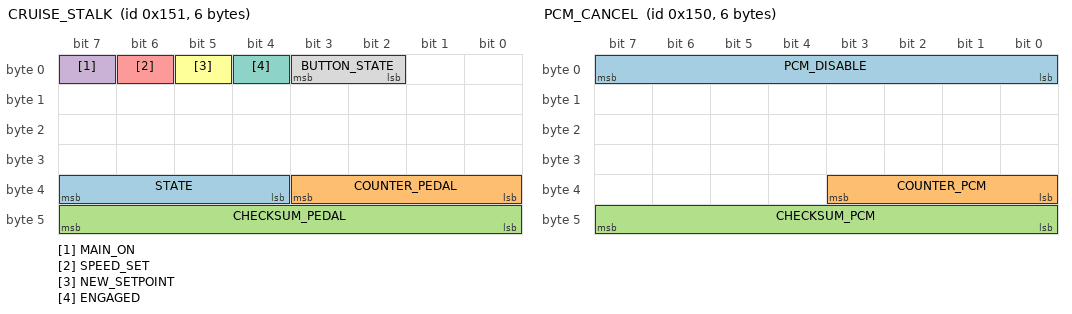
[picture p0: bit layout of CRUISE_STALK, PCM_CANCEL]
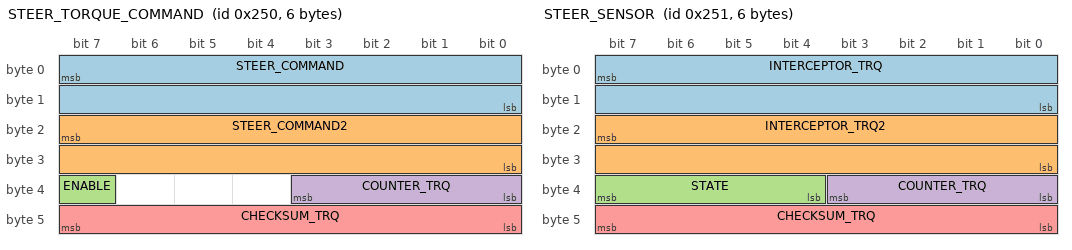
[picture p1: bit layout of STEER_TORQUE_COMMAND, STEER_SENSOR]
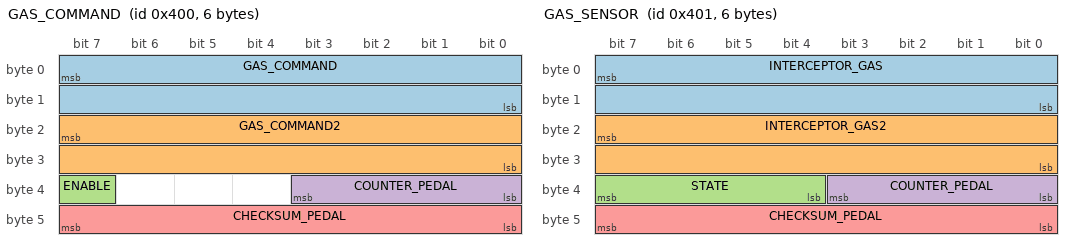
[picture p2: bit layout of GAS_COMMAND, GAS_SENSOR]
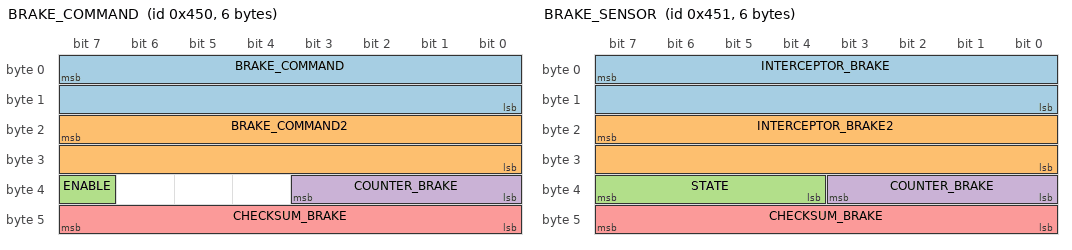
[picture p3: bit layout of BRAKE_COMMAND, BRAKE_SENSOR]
 BO_ 337 CRUISE_STALK: 6 INTERCEPTOR
  SG_ STATE : 39|4@0+ (1,0) [0|15] "" EON
  SG_ COUNTER_PEDAL : 35|4@0+ (1,0) [0|15] "" EON
  SG_ CHECKSUM_PEDAL : 47|8@0+ (1,0) [0|255] "" EON
  SG_ MAIN_ON : 7|1@0+ (1,0) [0|1] "" EON
  SG_ SPEED_SET : 6|1@0+ (1,0) [0|16383] "" XXX
  SG_ NEW_SETPOINT : 5|1@0+ (1,0) [0|3] "" XXX
  SG_ ENGAGED : 4|1@0+ (1,0) [0|3] "" XXX
  SG_ BUTTON_STATE : 2|2@1+ (1,0) [0|3] "" XXX

 BO_ 336 PCM_CANCEL: 6 EON
  SG_ PCM_DISABLE : 7|8@0+ (1,0) [0|1] "" INTERCEPTOR
  SG_ COUNTER_PCM : 35|4@0+ (1,0) [0|15] "" INTERCEPTOR
  SG_ CHECKSUM_PCM : 47|8@0+ (1,0) [0|255] "" INTERCEPTOR

 BO_ 592 STEER_TORQUE_COMMAND: 6 EON
  SG_ STEER_COMMAND : 7|16@0+ (1,0) [0|1] "" INTERCEPTOR
  SG_ STEER_COMMAND2 : 23|16@0+ (-1,0) [0|1] "" INTERCEPTOR
  SG_ ENABLE : 39|1@0+ (1,0) [0|1] "" INTERCEPTOR
  SG_ COUNTER_TRQ : 35|4@0+ (1,0) [0|15] "" INTERCEPTOR
  SG_ CHECKSUM_TRQ : 47|8@0+ (1,0) [0|255] "" INTERCEPTOR

 BO_ 593 STEER_SENSOR: 6 INTERCEPTOR
  SG_ INTERCEPTOR_TRQ : 7|16@0+ (0.00169433593750,-2.5) [0|1] "" EON
  SG_ INTERCEPTOR_TRQ2 : 23|16@0+ (0.00169433593750,-2.5) [0|1] "" EON
  SG_ STATE : 39|4@0+ (1,0) [0|15] "" EON
  SG_ COUNTER_TRQ : 35|4@0+ (1,0) [0|15] "" EON
  SG_ CHECKSUM_TRQ : 47|8@0+ (1,0) [0|255] "" EON

 VAL_ 593 STATE 5 "FAULT_TIMEOUT" 4 "FAULT_STARTUP" 3 "FAULT_SCE" 2 "FAULT_SEND" 1 "FAULT_BAD_CHECKSUM" 0 "NO_FAULT" ;

 BO_ 1024 GAS_COMMAND: 6 EON
  SG_ GAS_COMMAND : 7|16@0+ (0.882353,-2888.8235) [0|1] "" INTERCEPTOR
  SG_ GAS_COMMAND2 : 23|16@0+ (0.882353,-2888.8235) [0|1] "" INTERCEPTOR
  SG_ ENABLE : 39|1@0+ (1,0) [0|1] "" INTERCEPTOR
  SG_ COUNTER_PEDAL : 35|4@0+ (1,0) [0|15] "" INTERCEPTOR
  SG_ CHECKSUM_PEDAL : 47|8@0+ (1,0) [0|255] "" INTERCEPTOR

 BO_ 1025 GAS_SENSOR: 6 INTERCEPTOR
  SG_ INTERCEPTOR_GAS : 7|16@0+ (1,0) [0|1] "" EON
  SG_ INTERCEPTOR_GAS2 : 23|16@0+ (1,0) [0|1] "" EON
  SG_ STATE : 39|4@0+ (1,0) [0|15] "" EON
  SG_ COUNTER_PEDAL : 35|4@0+ (1,0) [0|15] "" EON
  SG_ CHECKSUM_PEDAL : 47|8@0+ (1,0) [0|255] "" EON

 VAL_ 1025 STATE 5 "FAULT_TIMEOUT" 4 "FAULT_STARTUP" 3 "FAULT_SCE" 2 "FAULT_SEND" 1 "FAULT_BAD_CHECKSUM" 0 "NO_FAULT" ;

 BO_ 1104 BRAKE_COMMAND: 6 EON
  SG_ BRAKE_COMMAND : 7|16@0+ (0.882353,-2888.8235) [0|1] "" INTERCEPTOR
  SG_ BRAKE_COMMAND2 : 23|16@0+ (1,0) [0|1] "" INTERCEPTOR
  SG_ ENABLE : 39|1@0+ (1,0) [0|1] "" INTERCEPTOR
  SG_ COUNTER_BRAKE : 35|4@0+ (1,0) [0|15] "" INTERCEPTOR
  SG_ CHECKSUM_BRAKE : 47|8@0+ (1,0) [0|255] "" INTERCEPTOR

 BO_ 1105 BRAKE_SENSOR: 6 INTERCEPTOR
  SG_ INTERCEPTOR_BRAKE : 7|16@0+ (1,0) [0|1] "" EON
  SG_ INTERCEPTOR_BRAKE2 : 23|16@0+ (1,0) [0|1] "" EON
  SG_ STATE : 39|4@0+ (1,0) [0|15] "" EON
  SG_ COUNTER_BRAKE : 35|4@0+ (1,0) [0|15] "" EON
  SG_ CHECKSUM_BRAKE : 47|8@0+ (1,0) [0|255] "" EON

 VAL_ 1105 STATE 5 "FAULT_TIMEOUT" 4 "FAULT_STARTUP" 3 "FAULT_SCE" 2 "FAULT_SEND" 1 "FAULT_BAD_CHECKSUM" 0 "NO_FAULT" ;

VERSION ""

NS_ :

BS_:

BU_: XXX

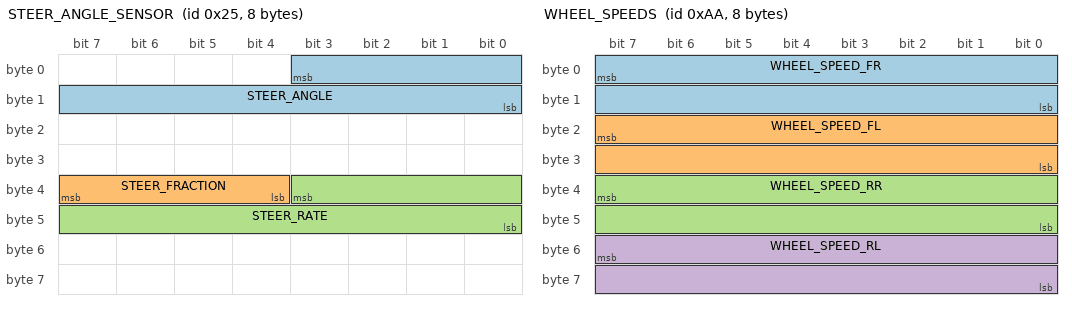
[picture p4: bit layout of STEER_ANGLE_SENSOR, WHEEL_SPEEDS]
BO_ 37 STEER_ANGLE_SENSOR: 8 XXX
 SG_ STEER_ANGLE : 3|12@0- (1.5,132) [-500|500] "deg" XXX
 SG_ STEER_FRACTION : 39|4@0- (0.1,0) [-0.7|0.7] "deg" XXX
 SG_ STEER_RATE : 35|12@0- (1,0) [-2000|2000] "deg/s" XXX

BO_ 170 WHEEL_SPEEDS: 8 XXX
 SG_ WHEEL_SPEED_FR : 7|16@0+ (0.01,-67.67) [0|250] "kph" XXX
 SG_ WHEEL_SPEED_FL : 23|16@0+ (0.01,-67.67) [0|250] "kph" XXX
 SG_ WHEEL_SPEED_RR : 39|16@0+ (0.01,-67.67) [0|250] "kph" XXX
 SG_ WHEEL_SPEED_RL : 55|16@0+ (0.01,-67.67) [0|250] "kph" XXX

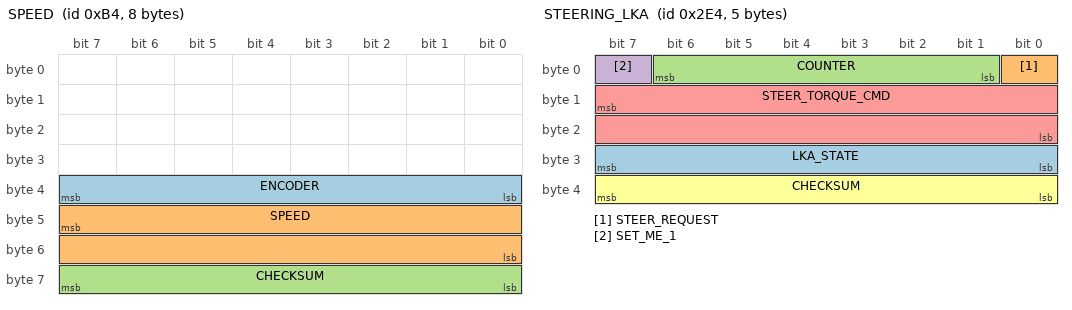
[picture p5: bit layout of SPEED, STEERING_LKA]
BO_ 180 SPEED: 8 XXX
 SG_ ENCODER : 39|8@0+ (1,0) [0|255] "" XXX
 SG_ SPEED : 47|16@0+ (0.01,0) [0|250] "kph" XXX
 SG_ CHECKSUM : 63|8@0+ (1,0) [0|255] "" XXX

BO_ 740 STEERING_LKA: 5 XXX
 SG_ LKA_STATE : 31|8@0+ (1,0) [0|255] "" XXX
 SG_ STEER_REQUEST : 0|1@0+ (1,0) [0|1] "" XXX
 SG_ COUNTER : 6|6@0+ (1,0) [0|63] "" XXX
 SG_ SET_ME_1 : 7|1@0+ (1,0) [0|1] "" XXX
 SG_ STEER_TORQUE_CMD : 15|16@0- (1,0) [0|65535] "" XXX
 SG_ CHECKSUM : 39|8@0+ (1,0) [0|255] "" XXX

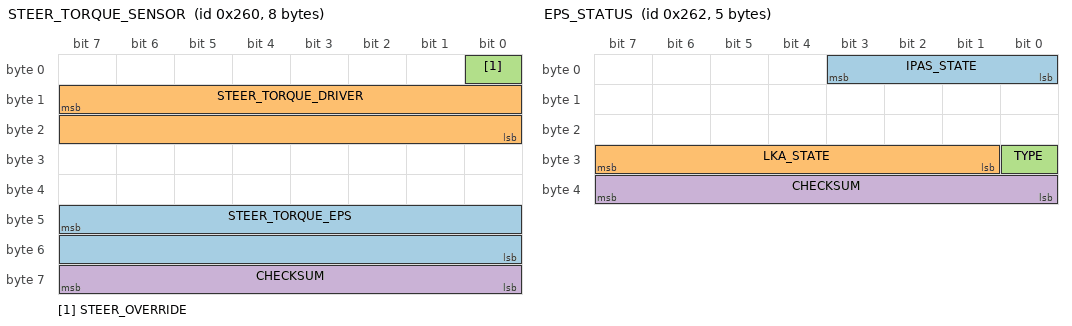
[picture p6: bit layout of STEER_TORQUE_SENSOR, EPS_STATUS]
BO_ 608 STEER_TORQUE_SENSOR: 8 XXX
 SG_ STEER_TORQUE_EPS : 47|16@0- (1.0,0) [-20000|20000] "" XXX
 SG_ STEER_TORQUE_DRIVER : 15|16@0- (1,0) [-32768|32767] "" XXX
 SG_ STEER_OVERRIDE : 0|1@0+ (1,0) [0|1] "" XXX
 SG_ CHECKSUM : 63|8@0+ (1,0) [0|255] "" XXX

BO_ 610 EPS_STATUS: 5 EPS
 SG_ IPAS_STATE : 3|4@0+ (1,0) [0|15] "" XXX
 SG_ LKA_STATE : 31|7@0+ (1,0) [0|127] "" XXX
 SG_ TYPE : 24|1@0+ (1,0) [0|1] "" XXX
 SG_ CHECKSUM : 39|8@0+ (1,0) [0|255] "" XXX
